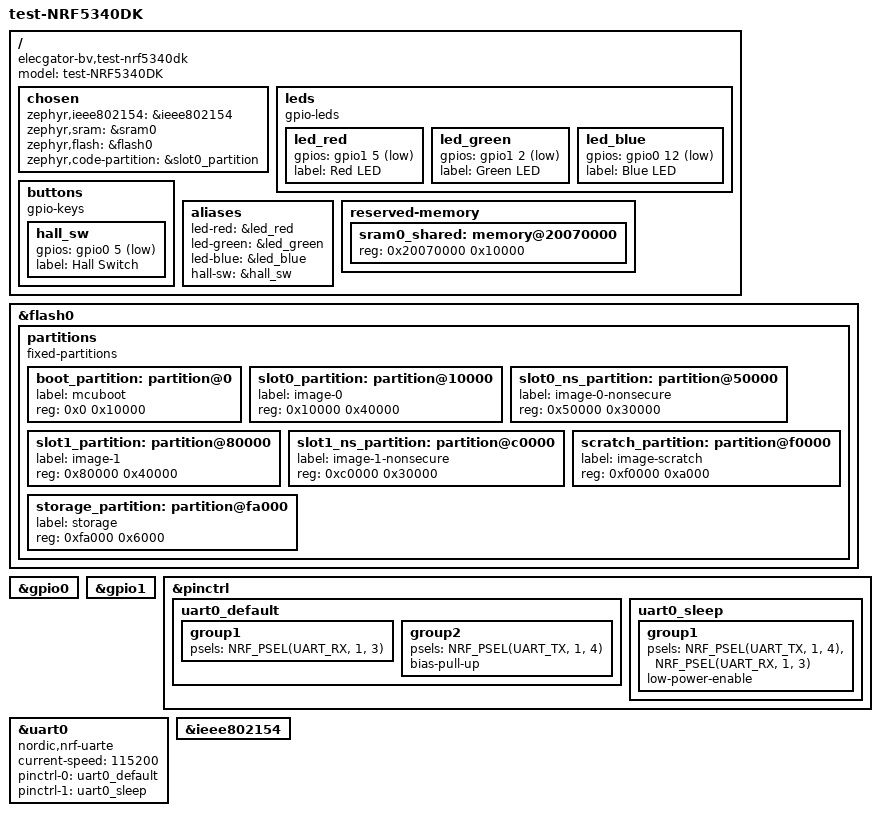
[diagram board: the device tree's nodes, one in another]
// Copyright (c) 2023 Nordic Semiconductor ASA
// SPDX-License-Identifier: Apache-2.0

/dts-v1/;
#include <nordic/nrf5340_cpuapp_qkaa.dtsi>

/ {
	model = "test-NRF5340DK";
	compatible = "elecgator-bv,test-nrf5340dk";

	chosen {
		zephyr,ieee802154 = &ieee802154;
		zephyr,sram = &sram0;
		zephyr,flash = &flash0;
		zephyr,code-partition = &slot0_partition;
	};

	leds {
		compatible = "gpio-leds";
		led_red: led_red {
			gpios = <&gpio1 5 GPIO_ACTIVE_LOW>;
			label = "Red LED";
		};
		led_green: led_green {
			gpios = <&gpio1 2 GPIO_ACTIVE_LOW>;
			label = "Green LED";
		};
		led_blue: led_blue {
			gpios = <&gpio0 12 GPIO_ACTIVE_LOW>;
			label = "Blue LED";
		};
	};

	buttons {
		compatible = "gpio-keys";
		hall_sw: hall_sw {
			gpios = <&gpio0 5 (GPIO_ACTIVE_LOW)>;
			label = "Hall Switch";
		};
	};

	aliases {
		led-red = &led_red;
		led-green = &led_green;
		led-blue = &led_blue;
		hall-sw = &hall_sw;
	};

	reserved-memory {
        #address-cells = <1>;
        #size-cells = <1>;
        ranges;


        //sram0_ns: image_ns@20000000 {
            /* Non-Secure image memory */
        //};
        sram0_shared: memory@20070000 {
            /* SRAM allocated to shared memory */
            reg = <0x20070000 0x10000>;
        };
    };
};



&flash0 {
	partitions {
		compatible = "fixed-partitions";
		#address-cells = <1>;
		#size-cells = <1>;

		boot_partition: partition@0 {
			label = "mcuboot";
			reg = <0x0 0x10000>;
		};
		slot0_partition: partition@10000 {
			label = "image-0";
			reg = <0x10000 0x40000>;
		};
		slot0_ns_partition: partition@50000 {
			label = "image-0-nonsecure";
			reg = <0x50000 0x30000>;
		};
		slot1_partition: partition@80000 {
			label = "image-1";
			reg = <0x80000 0x40000>;
		};
		slot1_ns_partition: partition@c0000 {
			label = "image-1-nonsecure";
			reg = <0xc0000 0x30000>;
		};
		scratch_partition: partition@f0000 {
			label = "image-scratch";
			reg = <0xf0000 0xa000>;
		};
		storage_partition: partition@fa000 {
			label = "storage";
			reg = <0xfa000 0x6000>;
		};
	};
};

&gpio0 {
	status = "okay";
};

&gpio1 {
	status = "okay";
};

&pinctrl {
	status = "okay";

	uart0_default: uart0_default {
		group1 {
			psels = <NRF_PSEL(UART_RX, 1, 3)>;
		};

		group2 {
			psels = <NRF_PSEL(UART_TX, 1, 4)>;
			bias-pull-up;
		};
	};

	uart0_sleep: uart0_sleep {
		group1 {
			psels = <NRF_PSEL(UART_TX, 1, 4)>,
				<NRF_PSEL(UART_RX,  1, 3)>;
			low-power-enable;
		};
	};
};

&uart0 {
	compatible = "nordic,nrf-uarte";
	status = "okay";
	current-speed = <115200>;
	pinctrl-0 = <&uart0_default>;
	pinctrl-1 = <&uart0_sleep>;
	pinctrl-names = "default", "sleep";
};

&ieee802154 {
	status = "okay";
};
